# ESP32-S31 register map
Vendor: ESPRESSIF SYSTEMS (SHANGHAI) CO., LTD.; Series: ESP32 S-Series; File version: 1
CPU: RV32IMAFC r0p0, little endian, no MPU, FPU, 0 interrupt priority bits
Address unit: 32 bits
Registers are 32-bit, read-write, reset 0x0 unless marked. A register's access mark holds for its fields unless they carry their own. Offsets are from the block's base; [hi:lo] are bit positions; {n}, {i} and the like mark numbered series.

## HP_PERI1_PMS — HP_PERI1_PMS Peripheral
Base 0x2058A000
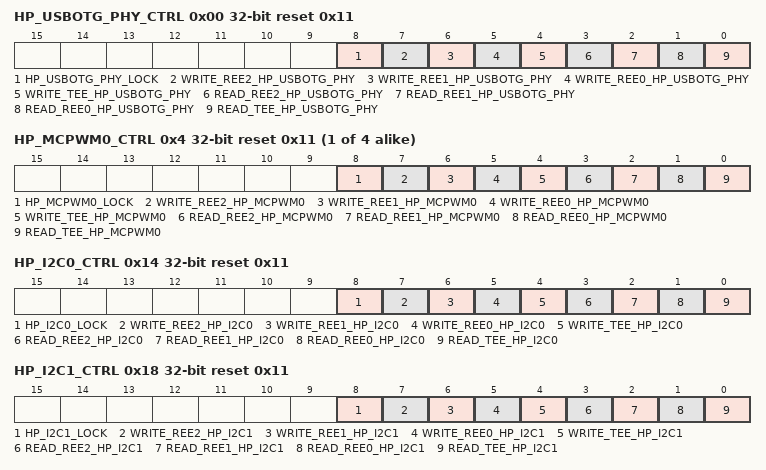
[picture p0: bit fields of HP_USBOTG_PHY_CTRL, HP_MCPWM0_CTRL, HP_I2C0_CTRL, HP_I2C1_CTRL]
0x00 HP_USBOTG_PHY_CTRL reset 0x11 — hp_usbotg_phy read/write control register
  [8] HP_USBOTG_PHY_LOCK — Set 1 to lock hp_usbotg_phy peri_apm configuration
  [7] WRITE_REE2_HP_USBOTG_PHY — Configures hp_usbotg_phy registers write permission in ree2 mode.\\ 0: can not be write \\ 1: can be write \\
  [6] WRITE_REE1_HP_USBOTG_PHY — Configures hp_usbotg_phy registers write permission in ree1 mode.\\ 0: can not be write \\ 1: can be write \\
  [5] WRITE_REE0_HP_USBOTG_PHY — Configures hp_usbotg_phy registers write permission in ree0 mode.\\ 0: can not be write \\ 1: can be write \\
  [4] WRITE_TEE_HP_USBOTG_PHY — Configures hp_usbotg_phy registers write permission in tee mode.\\ 0: can not be write \\ 1: can be write \\
  [3] READ_REE2_HP_USBOTG_PHY — Configures hp_usbotg_phy registers read permission in ree2 mode.\\ 0: can not be read \\ 1: can be read \\
  [2] READ_REE1_HP_USBOTG_PHY — Configures hp_usbotg_phy registers read permission in ree1 mode.\\ 0: can not be read \\ 1: can be read \\
  [1] READ_REE0_HP_USBOTG_PHY — Configures hp_usbotg_phy registers read permission in ree0 mode.\\ 0: can not be read \\ 1: can be read \\
  [0] READ_TEE_HP_USBOTG_PHY — Configures hp_usbotg_phy registers read permission in tee mode.\\ 0: can not be read \\ 1: can be read \\
{0x4+4i} HP_MCPWM{i}_CTRL reset 0x11 (i=0..3) — hp_mcpwm{i} read/write control register
  [8] HP_MCPWM{i}_LOCK — Set 1 to lock hp_mcpwm{i} peri_apm configuration
  [7] WRITE_REE2_HP_MCPWM{i} — Configures hp_mcpwm{i} registers write permission in ree2 mode.\\ 0: can not be write \\ 1: can be write \\
  [6] WRITE_REE1_HP_MCPWM{i} — Configures hp_mcpwm{i} registers write permission in ree1 mode.\\ 0: can not be write \\ 1: can be write \\
  [5] WRITE_REE0_HP_MCPWM{i} — Configures hp_mcpwm{i} registers write permission in ree0 mode.\\ 0: can not be write \\ 1: can be write \\
  [4] WRITE_TEE_HP_MCPWM{i} — Configures hp_mcpwm{i} registers write permission in tee mode.\\ 0: can not be write \\ 1: can be write \\
  [3] READ_REE2_HP_MCPWM{i} — Configures hp_mcpwm{i} registers read permission in ree2 mode.\\ 0: can not be read \\ 1: can be read \\
  [2] READ_REE1_HP_MCPWM{i} — Configures hp_mcpwm{i} registers read permission in ree1 mode.\\ 0: can not be read \\ 1: can be read \\
  [1] READ_REE0_HP_MCPWM{i} — Configures hp_mcpwm{i} registers read permission in ree0 mode.\\ 0: can not be read \\ 1: can be read \\
  [0] READ_TEE_HP_MCPWM{i} — Configures hp_mcpwm{i} registers read permission in tee mode.\\ 0: can not be read \\ 1: can be read \\
0x14 HP_I2C0_CTRL reset 0x11 — hp_i2c0 read/write control register
  [8] HP_I2C0_LOCK — Set 1 to lock hp_i2c0 peri_apm configuration
  [7] WRITE_REE2_HP_I2C0 — Configures hp_i2c0 registers write permission in ree2 mode.\\ 0: can not be write \\ 1: can be write \\
  [6] WRITE_REE1_HP_I2C0 — Configures hp_i2c0 registers write permission in ree1 mode.\\ 0: can not be write \\ 1: can be write \\
  [5] WRITE_REE0_HP_I2C0 — Configures hp_i2c0 registers write permission in ree0 mode.\\ 0: can not be write \\ 1: can be write \\
  [4] WRITE_TEE_HP_I2C0 — Configures hp_i2c0 registers write permission in tee mode.\\ 0: can not be write \\ 1: can be write \\
  [3] READ_REE2_HP_I2C0 — Configures hp_i2c0 registers read permission in ree2 mode.\\ 0: can not be read \\ 1: can be read \\
  [2] READ_REE1_HP_I2C0 — Configures hp_i2c0 registers read permission in ree1 mode.\\ 0: can not be read \\ 1: can be read \\
  [1] READ_REE0_HP_I2C0 — Configures hp_i2c0 registers read permission in ree0 mode.\\ 0: can not be read \\ 1: can be read \\
  [0] READ_TEE_HP_I2C0 — Configures hp_i2c0 registers read permission in tee mode.\\ 0: can not be read \\ 1: can be read \\
0x18 HP_I2C1_CTRL reset 0x11 — hp_i2c1 read/write control register
  [8] HP_I2C1_LOCK — Set 1 to lock hp_i2c1 peri_apm configuration
  [7] WRITE_REE2_HP_I2C1 — Configures hp_i2c1 registers write permission in ree2 mode.\\ 0: can not be write \\ 1: can be write \\
  [6] WRITE_REE1_HP_I2C1 — Configures hp_i2c1 registers write permission in ree1 mode.\\ 0: can not be write \\ 1: can be write \\
  [5] WRITE_REE0_HP_I2C1 — Configures hp_i2c1 registers write permission in ree0 mode.\\ 0: can not be write \\ 1: can be write \\
  [4] WRITE_TEE_HP_I2C1 — Configures hp_i2c1 registers write permission in tee mode.\\ 0: can not be write \\ 1: can be write \\
  [3] READ_REE2_HP_I2C1 — Configures hp_i2c1 registers read permission in ree2 mode.\\ 0: can not be read \\ 1: can be read \\
  [2] READ_REE1_HP_I2C1 — Configures hp_i2c1 registers read permission in ree1 mode.\\ 0: can not be read \\ 1: can be read \\
  [1] READ_REE0_HP_I2C1 — Configures hp_i2c1 registers read permission in ree0 mode.\\ 0: can not be read \\ 1: can be read \\
  [0] READ_TEE_HP_I2C1 — Configures hp_i2c1 registers read permission in tee mode.\\ 0: can not be read \\ 1: can be read \\
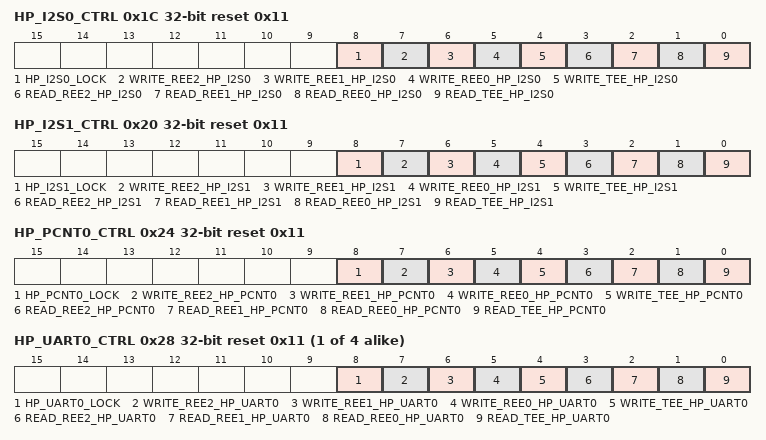
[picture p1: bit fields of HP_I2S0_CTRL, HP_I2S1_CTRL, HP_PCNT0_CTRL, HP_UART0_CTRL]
0x1C HP_I2S0_CTRL reset 0x11 — hp_i2s0 read/write control register
  [8] HP_I2S0_LOCK — Set 1 to lock hp_i2s0 peri_apm configuration
  [7] WRITE_REE2_HP_I2S0 — Configures hp_i2s0 registers write permission in ree2 mode.\\ 0: can not be write \\ 1: can be write \\
  [6] WRITE_REE1_HP_I2S0 — Configures hp_i2s0 registers write permission in ree1 mode.\\ 0: can not be write \\ 1: can be write \\
  [5] WRITE_REE0_HP_I2S0 — Configures hp_i2s0 registers write permission in ree0 mode.\\ 0: can not be write \\ 1: can be write \\
  [4] WRITE_TEE_HP_I2S0 — Configures hp_i2s0 registers write permission in tee mode.\\ 0: can not be write \\ 1: can be write \\
  [3] READ_REE2_HP_I2S0 — Configures hp_i2s0 registers read permission in ree2 mode.\\ 0: can not be read \\ 1: can be read \\
  [2] READ_REE1_HP_I2S0 — Configures hp_i2s0 registers read permission in ree1 mode.\\ 0: can not be read \\ 1: can be read \\
  [1] READ_REE0_HP_I2S0 — Configures hp_i2s0 registers read permission in ree0 mode.\\ 0: can not be read \\ 1: can be read \\
  [0] READ_TEE_HP_I2S0 — Configures hp_i2s0 registers read permission in tee mode.\\ 0: can not be read \\ 1: can be read \\
0x20 HP_I2S1_CTRL reset 0x11 — hp_i2s1 read/write control register
  [8] HP_I2S1_LOCK — Set 1 to lock hp_i2s1 peri_apm configuration
  [7] WRITE_REE2_HP_I2S1 — Configures hp_i2s1 registers write permission in ree2 mode.\\ 0: can not be write \\ 1: can be write \\
  [6] WRITE_REE1_HP_I2S1 — Configures hp_i2s1 registers write permission in ree1 mode.\\ 0: can not be write \\ 1: can be write \\
  [5] WRITE_REE0_HP_I2S1 — Configures hp_i2s1 registers write permission in ree0 mode.\\ 0: can not be write \\ 1: can be write \\
  [4] WRITE_TEE_HP_I2S1 — Configures hp_i2s1 registers write permission in tee mode.\\ 0: can not be write \\ 1: can be write \\
  [3] READ_REE2_HP_I2S1 — Configures hp_i2s1 registers read permission in ree2 mode.\\ 0: can not be read \\ 1: can be read \\
  [2] READ_REE1_HP_I2S1 — Configures hp_i2s1 registers read permission in ree1 mode.\\ 0: can not be read \\ 1: can be read \\
  [1] READ_REE0_HP_I2S1 — Configures hp_i2s1 registers read permission in ree0 mode.\\ 0: can not be read \\ 1: can be read \\
  [0] READ_TEE_HP_I2S1 — Configures hp_i2s1 registers read permission in tee mode.\\ 0: can not be read \\ 1: can be read \\
0x24 HP_PCNT0_CTRL reset 0x11 — hp_pcnt0 read/write control register
  [8] HP_PCNT0_LOCK — Set 1 to lock hp_pcnt0 peri_apm configuration
  [7] WRITE_REE2_HP_PCNT0 — Configures hp_pcnt0 registers write permission in ree2 mode.\\ 0: can not be write \\ 1: can be write \\
  [6] WRITE_REE1_HP_PCNT0 — Configures hp_pcnt0 registers write permission in ree1 mode.\\ 0: can not be write \\ 1: can be write \\
  [5] WRITE_REE0_HP_PCNT0 — Configures hp_pcnt0 registers write permission in ree0 mode.\\ 0: can not be write \\ 1: can be write \\
  [4] WRITE_TEE_HP_PCNT0 — Configures hp_pcnt0 registers write permission in tee mode.\\ 0: can not be write \\ 1: can be write \\
  [3] READ_REE2_HP_PCNT0 — Configures hp_pcnt0 registers read permission in ree2 mode.\\ 0: can not be read \\ 1: can be read \\
  [2] READ_REE1_HP_PCNT0 — Configures hp_pcnt0 registers read permission in ree1 mode.\\ 0: can not be read \\ 1: can be read \\
  [1] READ_REE0_HP_PCNT0 — Configures hp_pcnt0 registers read permission in ree0 mode.\\ 0: can not be read \\ 1: can be read \\
  [0] READ_TEE_HP_PCNT0 — Configures hp_pcnt0 registers read permission in tee mode.\\ 0: can not be read \\ 1: can be read \\
{0x28+4i} HP_UART{i}_CTRL reset 0x11 (i=0..3) — hp_uart{i} read/write control register
  [8] HP_UART{i}_LOCK — Set 1 to lock hp_uart{i} peri_apm configuration
  [7] WRITE_REE2_HP_UART{i} — Configures hp_uart{i} registers write permission in ree2 mode.\\ 0: can not be write \\ 1: can be write \\
  [6] WRITE_REE1_HP_UART{i} — Configures hp_uart{i} registers write permission in ree1 mode.\\ 0: can not be write \\ 1: can be write \\
  [5] WRITE_REE0_HP_UART{i} — Configures hp_uart{i} registers write permission in ree0 mode.\\ 0: can not be write \\ 1: can be write \\
  [4] WRITE_TEE_HP_UART{i} — Configures hp_uart{i} registers write permission in tee mode.\\ 0: can not be write \\ 1: can be write \\
  [3] READ_REE2_HP_UART{i} — Configures hp_uart{i} registers read permission in ree2 mode.\\ 0: can not be read \\ 1: can be read \\
  [2] READ_REE1_HP_UART{i} — Configures hp_uart{i} registers read permission in ree1 mode.\\ 0: can not be read \\ 1: can be read \\
  [1] READ_REE0_HP_UART{i} — Configures hp_uart{i} registers read permission in ree0 mode.\\ 0: can not be read \\ 1: can be read \\
  [0] READ_TEE_HP_UART{i} — Configures hp_uart{i} registers read permission in tee mode.\\ 0: can not be read \\ 1: can be read \\
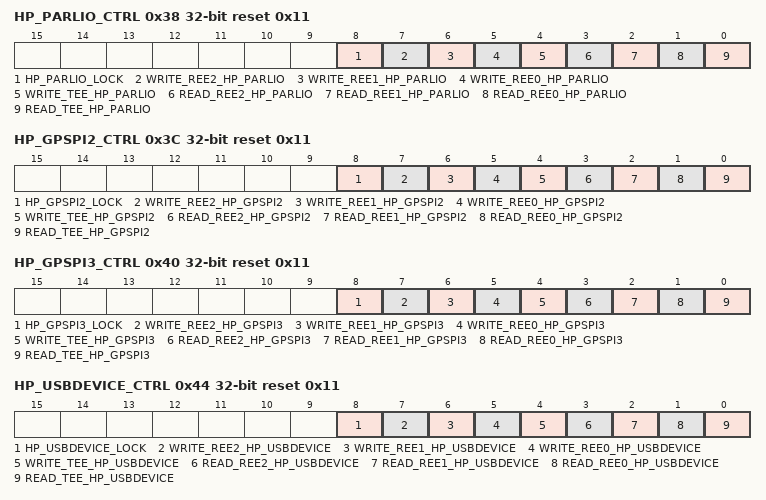
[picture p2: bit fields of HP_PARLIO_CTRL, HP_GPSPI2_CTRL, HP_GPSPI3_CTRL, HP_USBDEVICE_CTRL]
0x38 HP_PARLIO_CTRL reset 0x11 — hp_parlio read/write control register
  [8] HP_PARLIO_LOCK — Set 1 to lock hp_parlio peri_apm configuration
  [7] WRITE_REE2_HP_PARLIO — Configures hp_parlio registers write permission in ree2 mode.\\ 0: can not be write \\ 1: can be write \\
  [6] WRITE_REE1_HP_PARLIO — Configures hp_parlio registers write permission in ree1 mode.\\ 0: can not be write \\ 1: can be write \\
  [5] WRITE_REE0_HP_PARLIO — Configures hp_parlio registers write permission in ree0 mode.\\ 0: can not be write \\ 1: can be write \\
  [4] WRITE_TEE_HP_PARLIO — Configures hp_parlio registers write permission in tee mode.\\ 0: can not be write \\ 1: can be write \\
  [3] READ_REE2_HP_PARLIO — Configures hp_parlio registers read permission in ree2 mode.\\ 0: can not be read \\ 1: can be read \\
  [2] READ_REE1_HP_PARLIO — Configures hp_parlio registers read permission in ree1 mode.\\ 0: can not be read \\ 1: can be read \\
  [1] READ_REE0_HP_PARLIO — Configures hp_parlio registers read permission in ree0 mode.\\ 0: can not be read \\ 1: can be read \\
  [0] READ_TEE_HP_PARLIO — Configures hp_parlio registers read permission in tee mode.\\ 0: can not be read \\ 1: can be read \\
0x3C HP_GPSPI2_CTRL reset 0x11 — hp_gpspi2 read/write control register
  [8] HP_GPSPI2_LOCK — Set 1 to lock hp_gpspi2 peri_apm configuration
  [7] WRITE_REE2_HP_GPSPI2 — Configures hp_gpspi2 registers write permission in ree2 mode.\\ 0: can not be write \\ 1: can be write \\
  [6] WRITE_REE1_HP_GPSPI2 — Configures hp_gpspi2 registers write permission in ree1 mode.\\ 0: can not be write \\ 1: can be write \\
  [5] WRITE_REE0_HP_GPSPI2 — Configures hp_gpspi2 registers write permission in ree0 mode.\\ 0: can not be write \\ 1: can be write \\
  [4] WRITE_TEE_HP_GPSPI2 — Configures hp_gpspi2 registers write permission in tee mode.\\ 0: can not be write \\ 1: can be write \\
  [3] READ_REE2_HP_GPSPI2 — Configures hp_gpspi2 registers read permission in ree2 mode.\\ 0: can not be read \\ 1: can be read \\
  [2] READ_REE1_HP_GPSPI2 — Configures hp_gpspi2 registers read permission in ree1 mode.\\ 0: can not be read \\ 1: can be read \\
  [1] READ_REE0_HP_GPSPI2 — Configures hp_gpspi2 registers read permission in ree0 mode.\\ 0: can not be read \\ 1: can be read \\
  [0] READ_TEE_HP_GPSPI2 — Configures hp_gpspi2 registers read permission in tee mode.\\ 0: can not be read \\ 1: can be read \\
0x40 HP_GPSPI3_CTRL reset 0x11 — hp_gpspi3 read/write control register
  [8] HP_GPSPI3_LOCK — Set 1 to lock hp_gpspi3 peri_apm configuration
  [7] WRITE_REE2_HP_GPSPI3 — Configures hp_gpspi3 registers write permission in ree2 mode.\\ 0: can not be write \\ 1: can be write \\
  [6] WRITE_REE1_HP_GPSPI3 — Configures hp_gpspi3 registers write permission in ree1 mode.\\ 0: can not be write \\ 1: can be write \\
  [5] WRITE_REE0_HP_GPSPI3 — Configures hp_gpspi3 registers write permission in ree0 mode.\\ 0: can not be write \\ 1: can be write \\
  [4] WRITE_TEE_HP_GPSPI3 — Configures hp_gpspi3 registers write permission in tee mode.\\ 0: can not be write \\ 1: can be write \\
  [3] READ_REE2_HP_GPSPI3 — Configures hp_gpspi3 registers read permission in ree2 mode.\\ 0: can not be read \\ 1: can be read \\
  [2] READ_REE1_HP_GPSPI3 — Configures hp_gpspi3 registers read permission in ree1 mode.\\ 0: can not be read \\ 1: can be read \\
  [1] READ_REE0_HP_GPSPI3 — Configures hp_gpspi3 registers read permission in ree0 mode.\\ 0: can not be read \\ 1: can be read \\
  [0] READ_TEE_HP_GPSPI3 — Configures hp_gpspi3 registers read permission in tee mode.\\ 0: can not be read \\ 1: can be read \\
0x44 HP_USBDEVICE_CTRL reset 0x11 — hp_usbdevice read/write control register
  [8] HP_USBDEVICE_LOCK — Set 1 to lock hp_usbdevice peri_apm configuration
  [7] WRITE_REE2_HP_USBDEVICE — Configures hp_usbdevice registers write permission in ree2 mode.\\ 0: can not be write \\ 1: can be write \\
  [6] WRITE_REE1_HP_USBDEVICE — Configures hp_usbdevice registers write permission in ree1 mode.\\ 0: can not be write \\ 1: can be write \\
  [5] WRITE_REE0_HP_USBDEVICE — Configures hp_usbdevice registers write permission in ree0 mode.\\ 0: can not be write \\ 1: can be write \\
  [4] WRITE_TEE_HP_USBDEVICE — Configures hp_usbdevice registers write permission in tee mode.\\ 0: can not be write \\ 1: can be write \\
  [3] READ_REE2_HP_USBDEVICE — Configures hp_usbdevice registers read permission in ree2 mode.\\ 0: can not be read \\ 1: can be read \\
  [2] READ_REE1_HP_USBDEVICE — Configures hp_usbdevice registers read permission in ree1 mode.\\ 0: can not be read \\ 1: can be read \\
  [1] READ_REE0_HP_USBDEVICE — Configures hp_usbdevice registers read permission in ree0 mode.\\ 0: can not be read \\ 1: can be read \\
  [0] READ_TEE_HP_USBDEVICE — Configures hp_usbdevice registers read permission in tee mode.\\ 0: can not be read \\ 1: can be read \\
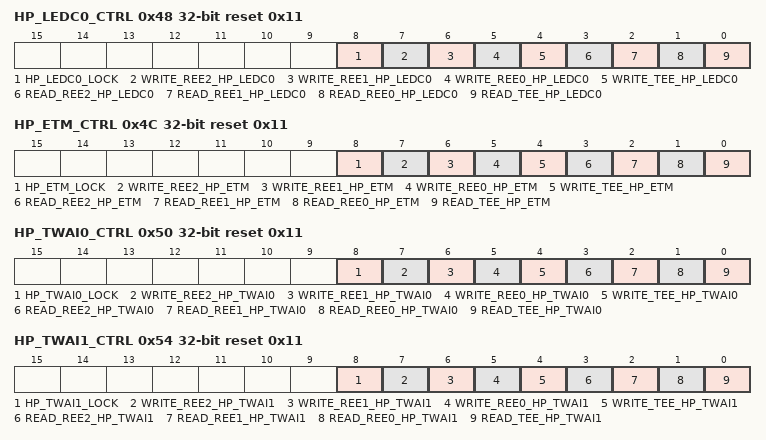
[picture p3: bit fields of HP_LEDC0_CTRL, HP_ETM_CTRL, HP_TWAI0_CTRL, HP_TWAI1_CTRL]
0x48 HP_LEDC0_CTRL reset 0x11 — hp_ledc0 read/write control register
  [8] HP_LEDC0_LOCK — Set 1 to lock hp_ledc0 peri_apm configuration
  [7] WRITE_REE2_HP_LEDC0 — Configures hp_ledc0 registers write permission in ree2 mode.\\ 0: can not be write \\ 1: can be write \\
  [6] WRITE_REE1_HP_LEDC0 — Configures hp_ledc0 registers write permission in ree1 mode.\\ 0: can not be write \\ 1: can be write \\
  [5] WRITE_REE0_HP_LEDC0 — Configures hp_ledc0 registers write permission in ree0 mode.\\ 0: can not be write \\ 1: can be write \\
  [4] WRITE_TEE_HP_LEDC0 — Configures hp_ledc0 registers write permission in tee mode.\\ 0: can not be write \\ 1: can be write \\
  [3] READ_REE2_HP_LEDC0 — Configures hp_ledc0 registers read permission in ree2 mode.\\ 0: can not be read \\ 1: can be read \\
  [2] READ_REE1_HP_LEDC0 — Configures hp_ledc0 registers read permission in ree1 mode.\\ 0: can not be read \\ 1: can be read \\
  [1] READ_REE0_HP_LEDC0 — Configures hp_ledc0 registers read permission in ree0 mode.\\ 0: can not be read \\ 1: can be read \\
  [0] READ_TEE_HP_LEDC0 — Configures hp_ledc0 registers read permission in tee mode.\\ 0: can not be read \\ 1: can be read \\
0x4C HP_ETM_CTRL reset 0x11 — hp_etm read/write control register
  [8] HP_ETM_LOCK — Set 1 to lock hp_etm peri_apm configuration
  [7] WRITE_REE2_HP_ETM — Configures hp_etm registers write permission in ree2 mode.\\ 0: can not be write \\ 1: can be write \\
  [6] WRITE_REE1_HP_ETM — Configures hp_etm registers write permission in ree1 mode.\\ 0: can not be write \\ 1: can be write \\
  [5] WRITE_REE0_HP_ETM — Configures hp_etm registers write permission in ree0 mode.\\ 0: can not be write \\ 1: can be write \\
  [4] WRITE_TEE_HP_ETM — Configures hp_etm registers write permission in tee mode.\\ 0: can not be write \\ 1: can be write \\
  [3] READ_REE2_HP_ETM — Configures hp_etm registers read permission in ree2 mode.\\ 0: can not be read \\ 1: can be read \\
  [2] READ_REE1_HP_ETM — Configures hp_etm registers read permission in ree1 mode.\\ 0: can not be read \\ 1: can be read \\
  [1] READ_REE0_HP_ETM — Configures hp_etm registers read permission in ree0 mode.\\ 0: can not be read \\ 1: can be read \\
  [0] READ_TEE_HP_ETM — Configures hp_etm registers read permission in tee mode.\\ 0: can not be read \\ 1: can be read \\
0x50 HP_TWAI0_CTRL reset 0x11 — hp_twai0 read/write control register
  [8] HP_TWAI0_LOCK — Set 1 to lock hp_twai0 peri_apm configuration
  [7] WRITE_REE2_HP_TWAI0 — Configures hp_twai0 registers write permission in ree2 mode.\\ 0: can not be write \\ 1: can be write \\
  [6] WRITE_REE1_HP_TWAI0 — Configures hp_twai0 registers write permission in ree1 mode.\\ 0: can not be write \\ 1: can be write \\
  [5] WRITE_REE0_HP_TWAI0 — Configures hp_twai0 registers write permission in ree0 mode.\\ 0: can not be write \\ 1: can be write \\
  [4] WRITE_TEE_HP_TWAI0 — Configures hp_twai0 registers write permission in tee mode.\\ 0: can not be write \\ 1: can be write \\
  [3] READ_REE2_HP_TWAI0 — Configures hp_twai0 registers read permission in ree2 mode.\\ 0: can not be read \\ 1: can be read \\
  [2] READ_REE1_HP_TWAI0 — Configures hp_twai0 registers read permission in ree1 mode.\\ 0: can not be read \\ 1: can be read \\
  [1] READ_REE0_HP_TWAI0 — Configures hp_twai0 registers read permission in ree0 mode.\\ 0: can not be read \\ 1: can be read \\
  [0] READ_TEE_HP_TWAI0 — Configures hp_twai0 registers read permission in tee mode.\\ 0: can not be read \\ 1: can be read \\
0x54 HP_TWAI1_CTRL reset 0x11 — hp_twai1 read/write control register
  [8] HP_TWAI1_LOCK — Set 1 to lock hp_twai1 peri_apm configuration
  [7] WRITE_REE2_HP_TWAI1 — Configures hp_twai1 registers write permission in ree2 mode.\\ 0: can not be write \\ 1: can be write \\
  [6] WRITE_REE1_HP_TWAI1 — Configures hp_twai1 registers write permission in ree1 mode.\\ 0: can not be write \\ 1: can be write \\
  [5] WRITE_REE0_HP_TWAI1 — Configures hp_twai1 registers write permission in ree0 mode.\\ 0: can not be write \\ 1: can be write \\
  [4] WRITE_TEE_HP_TWAI1 — Configures hp_twai1 registers write permission in tee mode.\\ 0: can not be write \\ 1: can be write \\
  [3] READ_REE2_HP_TWAI1 — Configures hp_twai1 registers read permission in ree2 mode.\\ 0: can not be read \\ 1: can be read \\
  [2] READ_REE1_HP_TWAI1 — Configures hp_twai1 registers read permission in ree1 mode.\\ 0: can not be read \\ 1: can be read \\
  [1] READ_REE0_HP_TWAI1 — Configures hp_twai1 registers read permission in ree0 mode.\\ 0: can not be read \\ 1: can be read \\
  [0] READ_TEE_HP_TWAI1 — Configures hp_twai1 registers read permission in tee mode.\\ 0: can not be read \\ 1: can be read \\
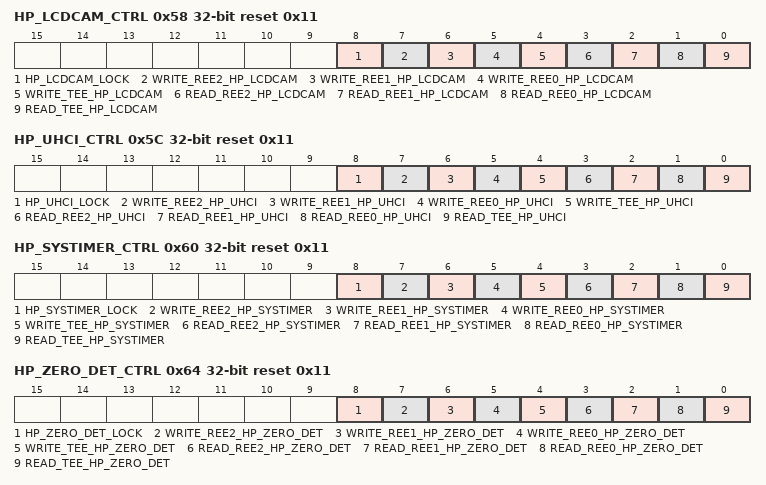
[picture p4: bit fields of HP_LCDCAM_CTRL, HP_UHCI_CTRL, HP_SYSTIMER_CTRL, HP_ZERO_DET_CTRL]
0x58 HP_LCDCAM_CTRL reset 0x11 — hp_lcdcam read/write control register
  [8] HP_LCDCAM_LOCK — Set 1 to lock hp_lcdcam peri_apm configuration
  [7] WRITE_REE2_HP_LCDCAM — Configures hp_lcdcam registers write permission in ree2 mode.\\ 0: can not be write \\ 1: can be write \\
  [6] WRITE_REE1_HP_LCDCAM — Configures hp_lcdcam registers write permission in ree1 mode.\\ 0: can not be write \\ 1: can be write \\
  [5] WRITE_REE0_HP_LCDCAM — Configures hp_lcdcam registers write permission in ree0 mode.\\ 0: can not be write \\ 1: can be write \\
  [4] WRITE_TEE_HP_LCDCAM — Configures hp_lcdcam registers write permission in tee mode.\\ 0: can not be write \\ 1: can be write \\
  [3] READ_REE2_HP_LCDCAM — Configures hp_lcdcam registers read permission in ree2 mode.\\ 0: can not be read \\ 1: can be read \\
  [2] READ_REE1_HP_LCDCAM — Configures hp_lcdcam registers read permission in ree1 mode.\\ 0: can not be read \\ 1: can be read \\
  [1] READ_REE0_HP_LCDCAM — Configures hp_lcdcam registers read permission in ree0 mode.\\ 0: can not be read \\ 1: can be read \\
  [0] READ_TEE_HP_LCDCAM — Configures hp_lcdcam registers read permission in tee mode.\\ 0: can not be read \\ 1: can be read \\
0x5C HP_UHCI_CTRL reset 0x11 — hp_uhci read/write control register
  [8] HP_UHCI_LOCK — Set 1 to lock hp_uhci peri_apm configuration
  [7] WRITE_REE2_HP_UHCI — Configures hp_uhci registers write permission in ree2 mode.\\ 0: can not be write \\ 1: can be write \\
  [6] WRITE_REE1_HP_UHCI — Configures hp_uhci registers write permission in ree1 mode.\\ 0: can not be write \\ 1: can be write \\
  [5] WRITE_REE0_HP_UHCI — Configures hp_uhci registers write permission in ree0 mode.\\ 0: can not be write \\ 1: can be write \\
  [4] WRITE_TEE_HP_UHCI — Configures hp_uhci registers write permission in tee mode.\\ 0: can not be write \\ 1: can be write \\
  [3] READ_REE2_HP_UHCI — Configures hp_uhci registers read permission in ree2 mode.\\ 0: can not be read \\ 1: can be read \\
  [2] READ_REE1_HP_UHCI — Configures hp_uhci registers read permission in ree1 mode.\\ 0: can not be read \\ 1: can be read \\
  [1] READ_REE0_HP_UHCI — Configures hp_uhci registers read permission in ree0 mode.\\ 0: can not be read \\ 1: can be read \\
  [0] READ_TEE_HP_UHCI — Configures hp_uhci registers read permission in tee mode.\\ 0: can not be read \\ 1: can be read \\
0x60 HP_SYSTIMER_CTRL reset 0x11 — hp_systimer read/write control register
  [8] HP_SYSTIMER_LOCK — Set 1 to lock hp_systimer peri_apm configuration
  [7] WRITE_REE2_HP_SYSTIMER — Configures hp_systimer registers write permission in ree2 mode.\\ 0: can not be write \\ 1: can be write \\
  [6] WRITE_REE1_HP_SYSTIMER — Configures hp_systimer registers write permission in ree1 mode.\\ 0: can not be write \\ 1: can be write \\
  [5] WRITE_REE0_HP_SYSTIMER — Configures hp_systimer registers write permission in ree0 mode.\\ 0: can not be write \\ 1: can be write \\
  [4] WRITE_TEE_HP_SYSTIMER — Configures hp_systimer registers write permission in tee mode.\\ 0: can not be write \\ 1: can be write \\
  [3] READ_REE2_HP_SYSTIMER — Configures hp_systimer registers read permission in ree2 mode.\\ 0: can not be read \\ 1: can be read \\
  [2] READ_REE1_HP_SYSTIMER — Configures hp_systimer registers read permission in ree1 mode.\\ 0: can not be read \\ 1: can be read \\
  [1] READ_REE0_HP_SYSTIMER — Configures hp_systimer registers read permission in ree0 mode.\\ 0: can not be read \\ 1: can be read \\
  [0] READ_TEE_HP_SYSTIMER — Configures hp_systimer registers read permission in tee mode.\\ 0: can not be read \\ 1: can be read \\
0x64 HP_ZERO_DET_CTRL reset 0x11 — hp_zero_det read/write control register
  [8] HP_ZERO_DET_LOCK — Set 1 to lock hp_zero_det peri_apm configuration
  [7] WRITE_REE2_HP_ZERO_DET — Configures hp_zero_det registers write permission in ree2 mode.\\ 0: can not be write \\ 1: can be write \\
  [6] WRITE_REE1_HP_ZERO_DET — Configures hp_zero_det registers write permission in ree1 mode.\\ 0: can not be write \\ 1: can be write \\
  [5] WRITE_REE0_HP_ZERO_DET — Configures hp_zero_det registers write permission in ree0 mode.\\ 0: can not be write \\ 1: can be write \\
  [4] WRITE_TEE_HP_ZERO_DET — Configures hp_zero_det registers write permission in tee mode.\\ 0: can not be write \\ 1: can be write \\
  [3] READ_REE2_HP_ZERO_DET — Configures hp_zero_det registers read permission in ree2 mode.\\ 0: can not be read \\ 1: can be read \\
  [2] READ_REE1_HP_ZERO_DET — Configures hp_zero_det registers read permission in ree1 mode.\\ 0: can not be read \\ 1: can be read \\
  [1] READ_REE0_HP_ZERO_DET — Configures hp_zero_det registers read permission in ree0 mode.\\ 0: can not be read \\ 1: can be read \\
  [0] READ_TEE_HP_ZERO_DET — Configures hp_zero_det registers read permission in tee mode.\\ 0: can not be read \\ 1: can be read \\
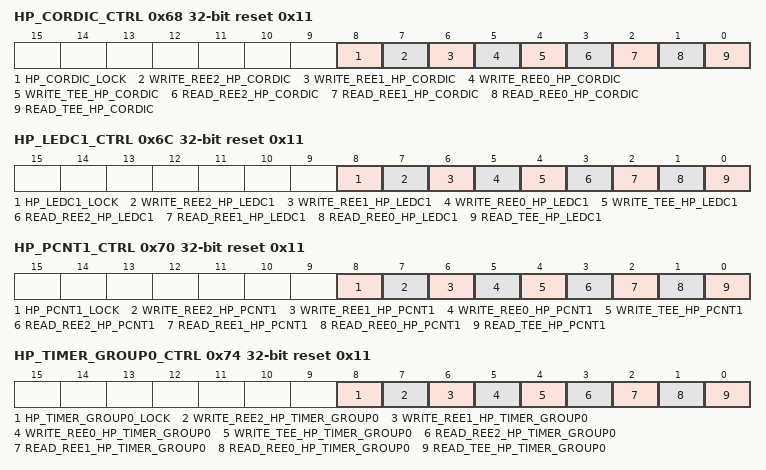
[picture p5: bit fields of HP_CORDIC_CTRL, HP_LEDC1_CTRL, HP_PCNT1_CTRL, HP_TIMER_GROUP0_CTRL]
0x68 HP_CORDIC_CTRL reset 0x11 — hp_cordic read/write control register
  [8] HP_CORDIC_LOCK — Set 1 to lock hp_cordic peri_apm configuration
  [7] WRITE_REE2_HP_CORDIC — Configures hp_cordic registers write permission in ree2 mode.\\ 0: can not be write \\ 1: can be write \\
  [6] WRITE_REE1_HP_CORDIC — Configures hp_cordic registers write permission in ree1 mode.\\ 0: can not be write \\ 1: can be write \\
  [5] WRITE_REE0_HP_CORDIC — Configures hp_cordic registers write permission in ree0 mode.\\ 0: can not be write \\ 1: can be write \\
  [4] WRITE_TEE_HP_CORDIC — Configures hp_cordic registers write permission in tee mode.\\ 0: can not be write \\ 1: can be write \\
  [3] READ_REE2_HP_CORDIC — Configures hp_cordic registers read permission in ree2 mode.\\ 0: can not be read \\ 1: can be read \\
  [2] READ_REE1_HP_CORDIC — Configures hp_cordic registers read permission in ree1 mode.\\ 0: can not be read \\ 1: can be read \\
  [1] READ_REE0_HP_CORDIC — Configures hp_cordic registers read permission in ree0 mode.\\ 0: can not be read \\ 1: can be read \\
  [0] READ_TEE_HP_CORDIC — Configures hp_cordic registers read permission in tee mode.\\ 0: can not be read \\ 1: can be read \\
0x6C HP_LEDC1_CTRL reset 0x11 — hp_ledc1 read/write control register
  [8] HP_LEDC1_LOCK — Set 1 to lock hp_ledc1 peri_apm configuration
  [7] WRITE_REE2_HP_LEDC1 — Configures hp_ledc1 registers write permission in ree2 mode.\\ 0: can not be write \\ 1: can be write \\
  [6] WRITE_REE1_HP_LEDC1 — Configures hp_ledc1 registers write permission in ree1 mode.\\ 0: can not be write \\ 1: can be write \\
  [5] WRITE_REE0_HP_LEDC1 — Configures hp_ledc1 registers write permission in ree0 mode.\\ 0: can not be write \\ 1: can be write \\
  [4] WRITE_TEE_HP_LEDC1 — Configures hp_ledc1 registers write permission in tee mode.\\ 0: can not be write \\ 1: can be write \\
  [3] READ_REE2_HP_LEDC1 — Configures hp_ledc1 registers read permission in ree2 mode.\\ 0: can not be read \\ 1: can be read \\
  [2] READ_REE1_HP_LEDC1 — Configures hp_ledc1 registers read permission in ree1 mode.\\ 0: can not be read \\ 1: can be read \\
  [1] READ_REE0_HP_LEDC1 — Configures hp_ledc1 registers read permission in ree0 mode.\\ 0: can not be read \\ 1: can be read \\
  [0] READ_TEE_HP_LEDC1 — Configures hp_ledc1 registers read permission in tee mode.\\ 0: can not be read \\ 1: can be read \\
0x70 HP_PCNT1_CTRL reset 0x11 — hp_pcnt1 read/write control register
  [8] HP_PCNT1_LOCK — Set 1 to lock hp_pcnt1 peri_apm configuration
  [7] WRITE_REE2_HP_PCNT1 — Configures hp_pcnt1 registers write permission in ree2 mode.\\ 0: can not be write \\ 1: can be write \\
  [6] WRITE_REE1_HP_PCNT1 — Configures hp_pcnt1 registers write permission in ree1 mode.\\ 0: can not be write \\ 1: can be write \\
  [5] WRITE_REE0_HP_PCNT1 — Configures hp_pcnt1 registers write permission in ree0 mode.\\ 0: can not be write \\ 1: can be write \\
  [4] WRITE_TEE_HP_PCNT1 — Configures hp_pcnt1 registers write permission in tee mode.\\ 0: can not be write \\ 1: can be write \\
  [3] READ_REE2_HP_PCNT1 — Configures hp_pcnt1 registers read permission in ree2 mode.\\ 0: can not be read \\ 1: can be read \\
  [2] READ_REE1_HP_PCNT1 — Configures hp_pcnt1 registers read permission in ree1 mode.\\ 0: can not be read \\ 1: can be read \\
  [1] READ_REE0_HP_PCNT1 — Configures hp_pcnt1 registers read permission in ree0 mode.\\ 0: can not be read \\ 1: can be read \\
  [0] READ_TEE_HP_PCNT1 — Configures hp_pcnt1 registers read permission in tee mode.\\ 0: can not be read \\ 1: can be read \\
0x74 HP_TIMER_GROUP0_CTRL reset 0x11 — hp_timer_group0 read/write control register
  [8] HP_TIMER_GROUP0_LOCK — Set 1 to lock hp_timer_group0 peri_apm configuration
  [7] WRITE_REE2_HP_TIMER_GROUP0 — Configures hp_timer_group0 registers write permission in ree2 mode.\\ 0: can not be write \\ 1: can be write \\
  [6] WRITE_REE1_HP_TIMER_GROUP0 — Configures hp_timer_group0 registers write permission in ree1 mode.\\ 0: can not be write \\ 1: can be write \\
  [5] WRITE_REE0_HP_TIMER_GROUP0 — Configures hp_timer_group0 registers write permission in ree0 mode.\\ 0: can not be write \\ 1: can be write \\
  [4] WRITE_TEE_HP_TIMER_GROUP0 — Configures hp_timer_group0 registers write permission in tee mode.\\ 0: can not be write \\ 1: can be write \\
  [3] READ_REE2_HP_TIMER_GROUP0 — Configures hp_timer_group0 registers read permission in ree2 mode.\\ 0: can not be read \\ 1: can be read \\
  [2] READ_REE1_HP_TIMER_GROUP0 — Configures hp_timer_group0 registers read permission in ree1 mode.\\ 0: can not be read \\ 1: can be read \\
  [1] READ_REE0_HP_TIMER_GROUP0 — Configures hp_timer_group0 registers read permission in ree0 mode.\\ 0: can not be read \\ 1: can be read \\
  [0] READ_TEE_HP_TIMER_GROUP0 — Configures hp_timer_group0 registers read permission in tee mode.\\ 0: can not be read \\ 1: can be read \\
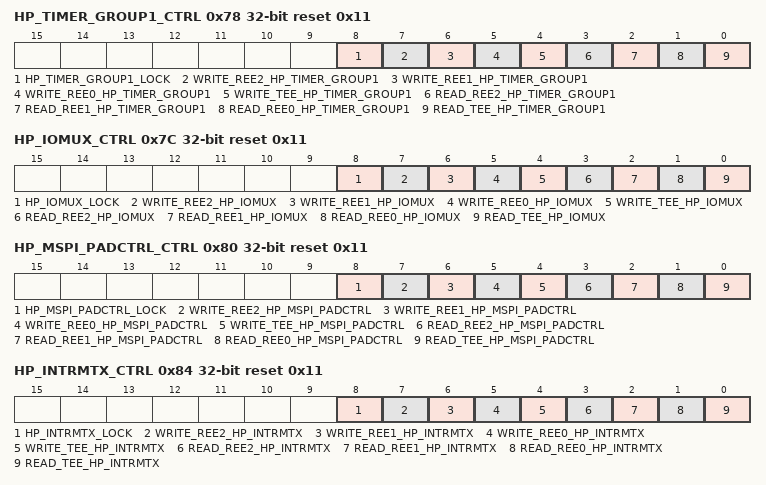
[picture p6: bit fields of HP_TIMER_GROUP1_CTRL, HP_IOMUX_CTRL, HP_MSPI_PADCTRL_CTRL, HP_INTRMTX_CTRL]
0x78 HP_TIMER_GROUP1_CTRL reset 0x11 — hp_timer_group1 read/write control register
  [8] HP_TIMER_GROUP1_LOCK — Set 1 to lock hp_timer_group1 peri_apm configuration
  [7] WRITE_REE2_HP_TIMER_GROUP1 — Configures hp_timer_group1 registers write permission in ree2 mode.\\ 0: can not be write \\ 1: can be write \\
  [6] WRITE_REE1_HP_TIMER_GROUP1 — Configures hp_timer_group1 registers write permission in ree1 mode.\\ 0: can not be write \\ 1: can be write \\
  [5] WRITE_REE0_HP_TIMER_GROUP1 — Configures hp_timer_group1 registers write permission in ree0 mode.\\ 0: can not be write \\ 1: can be write \\
  [4] WRITE_TEE_HP_TIMER_GROUP1 — Configures hp_timer_group1 registers write permission in tee mode.\\ 0: can not be write \\ 1: can be write \\
  [3] READ_REE2_HP_TIMER_GROUP1 — Configures hp_timer_group1 registers read permission in ree2 mode.\\ 0: can not be read \\ 1: can be read \\
  [2] READ_REE1_HP_TIMER_GROUP1 — Configures hp_timer_group1 registers read permission in ree1 mode.\\ 0: can not be read \\ 1: can be read \\
  [1] READ_REE0_HP_TIMER_GROUP1 — Configures hp_timer_group1 registers read permission in ree0 mode.\\ 0: can not be read \\ 1: can be read \\
  [0] READ_TEE_HP_TIMER_GROUP1 — Configures hp_timer_group1 registers read permission in tee mode.\\ 0: can not be read \\ 1: can be read \\
0x7C HP_IOMUX_CTRL reset 0x11 — hp_iomux read/write control register
  [8] HP_IOMUX_LOCK — Set 1 to lock hp_iomux peri_apm configuration
  [7] WRITE_REE2_HP_IOMUX — Configures hp_iomux registers write permission in ree2 mode.\\ 0: can not be write \\ 1: can be write \\
  [6] WRITE_REE1_HP_IOMUX — Configures hp_iomux registers write permission in ree1 mode.\\ 0: can not be write \\ 1: can be write \\
  [5] WRITE_REE0_HP_IOMUX — Configures hp_iomux registers write permission in ree0 mode.\\ 0: can not be write \\ 1: can be write \\
  [4] WRITE_TEE_HP_IOMUX — Configures hp_iomux registers write permission in tee mode.\\ 0: can not be write \\ 1: can be write \\
  [3] READ_REE2_HP_IOMUX — Configures hp_iomux registers read permission in ree2 mode.\\ 0: can not be read \\ 1: can be read \\
  [2] READ_REE1_HP_IOMUX — Configures hp_iomux registers read permission in ree1 mode.\\ 0: can not be read \\ 1: can be read \\
  [1] READ_REE0_HP_IOMUX — Configures hp_iomux registers read permission in ree0 mode.\\ 0: can not be read \\ 1: can be read \\
  [0] READ_TEE_HP_IOMUX — Configures hp_iomux registers read permission in tee mode.\\ 0: can not be read \\ 1: can be read \\
0x80 HP_MSPI_PADCTRL_CTRL reset 0x11 — hp_mspi_padctrl read/write control register
  [8] HP_MSPI_PADCTRL_LOCK — Set 1 to lock hp_mspi_padctrl peri_apm configuration
  [7] WRITE_REE2_HP_MSPI_PADCTRL — Configures hp_mspi_padctrl registers write permission in ree2 mode.\\ 0: can not be write \\ 1: can be write \\
  [6] WRITE_REE1_HP_MSPI_PADCTRL — Configures hp_mspi_padctrl registers write permission in ree1 mode.\\ 0: can not be write \\ 1: can be write \\
  [5] WRITE_REE0_HP_MSPI_PADCTRL — Configures hp_mspi_padctrl registers write permission in ree0 mode.\\ 0: can not be write \\ 1: can be write \\
  [4] WRITE_TEE_HP_MSPI_PADCTRL — Configures hp_mspi_padctrl registers write permission in tee mode.\\ 0: can not be write \\ 1: can be write \\
  [3] READ_REE2_HP_MSPI_PADCTRL — Configures hp_mspi_padctrl registers read permission in ree2 mode.\\ 0: can not be read \\ 1: can be read \\
  [2] READ_REE1_HP_MSPI_PADCTRL — Configures hp_mspi_padctrl registers read permission in ree1 mode.\\ 0: can not be read \\ 1: can be read \\
  [1] READ_REE0_HP_MSPI_PADCTRL — Configures hp_mspi_padctrl registers read permission in ree0 mode.\\ 0: can not be read \\ 1: can be read \\
  [0] READ_TEE_HP_MSPI_PADCTRL — Configures hp_mspi_padctrl registers read permission in tee mode.\\ 0: can not be read \\ 1: can be read \\
0x84 HP_INTRMTX_CTRL reset 0x11 — hp_intrmtx read/write control register
  [8] HP_INTRMTX_LOCK — Set 1 to lock hp_intrmtx peri_apm configuration
  [7] WRITE_REE2_HP_INTRMTX — Configures hp_intrmtx registers write permission in ree2 mode.\\ 0: can not be write \\ 1: can be write \\
  [6] WRITE_REE1_HP_INTRMTX — Configures hp_intrmtx registers write permission in ree1 mode.\\ 0: can not be write \\ 1: can be write \\
  [5] WRITE_REE0_HP_INTRMTX — Configures hp_intrmtx registers write permission in ree0 mode.\\ 0: can not be write \\ 1: can be write \\
  [4] WRITE_TEE_HP_INTRMTX — Configures hp_intrmtx registers write permission in tee mode.\\ 0: can not be write \\ 1: can be write \\
  [3] READ_REE2_HP_INTRMTX — Configures hp_intrmtx registers read permission in ree2 mode.\\ 0: can not be read \\ 1: can be read \\
  [2] READ_REE1_HP_INTRMTX — Configures hp_intrmtx registers read permission in ree1 mode.\\ 0: can not be read \\ 1: can be read \\
  [1] READ_REE0_HP_INTRMTX — Configures hp_intrmtx registers read permission in ree0 mode.\\ 0: can not be read \\ 1: can be read \\
  [0] READ_TEE_HP_INTRMTX — Configures hp_intrmtx registers read permission in tee mode.\\ 0: can not be read \\ 1: can be read \\
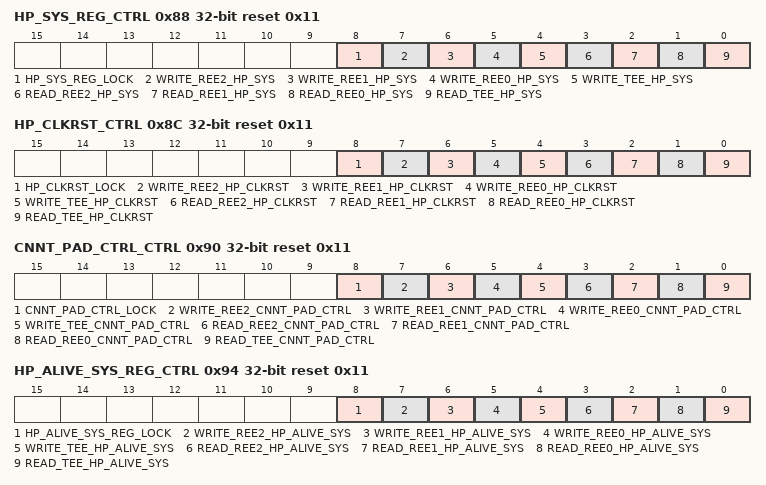
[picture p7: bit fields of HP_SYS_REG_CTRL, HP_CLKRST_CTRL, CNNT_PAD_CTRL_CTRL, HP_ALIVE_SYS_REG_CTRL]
0x88 HP_SYS_REG_CTRL reset 0x11 — hp_sys_reg read/write control register
  [8] HP_SYS_REG_LOCK — Set 1 to lock hp_sys_reg peri_apm configuration
  [7] WRITE_REE2_HP_SYS — Configures hp_sys_reg registers write permission in ree2 mode.\\ 0: can not be write \\ 1: can be write \\
  [6] WRITE_REE1_HP_SYS — Configures hp_sys_reg registers write permission in ree1 mode.\\ 0: can not be write \\ 1: can be write \\
  [5] WRITE_REE0_HP_SYS — Configures hp_sys_reg registers write permission in ree0 mode.\\ 0: can not be write \\ 1: can be write \\
  [4] WRITE_TEE_HP_SYS — Configures hp_sys_reg registers write permission in tee mode.\\ 0: can not be write \\ 1: can be write \\
  [3] READ_REE2_HP_SYS — Configures hp_sys_reg registers read permission in ree2 mode.\\ 0: can not be read \\ 1: can be read \\
  [2] READ_REE1_HP_SYS — Configures hp_sys_reg registers read permission in ree1 mode.\\ 0: can not be read \\ 1: can be read \\
  [1] READ_REE0_HP_SYS — Configures hp_sys_reg registers read permission in ree0 mode.\\ 0: can not be read \\ 1: can be read \\
  [0] READ_TEE_HP_SYS — Configures hp_sys_reg registers read permission in tee mode.\\ 0: can not be read \\ 1: can be read \\
0x8C HP_CLKRST_CTRL reset 0x11 — hp_clkrst read/write control register
  [8] HP_CLKRST_LOCK — Set 1 to lock hp_clkrst peri_apm configuration
  [7] WRITE_REE2_HP_CLKRST — Configures hp_clkrst registers write permission in ree2 mode.\\ 0: can not be write \\ 1: can be write \\
  [6] WRITE_REE1_HP_CLKRST — Configures hp_clkrst registers write permission in ree1 mode.\\ 0: can not be write \\ 1: can be write \\
  [5] WRITE_REE0_HP_CLKRST — Configures hp_clkrst registers write permission in ree0 mode.\\ 0: can not be write \\ 1: can be write \\
  [4] WRITE_TEE_HP_CLKRST — Configures hp_clkrst registers write permission in tee mode.\\ 0: can not be write \\ 1: can be write \\
  [3] READ_REE2_HP_CLKRST — Configures hp_clkrst registers read permission in ree2 mode.\\ 0: can not be read \\ 1: can be read \\
  [2] READ_REE1_HP_CLKRST — Configures hp_clkrst registers read permission in ree1 mode.\\ 0: can not be read \\ 1: can be read \\
  [1] READ_REE0_HP_CLKRST — Configures hp_clkrst registers read permission in ree0 mode.\\ 0: can not be read \\ 1: can be read \\
  [0] READ_TEE_HP_CLKRST — Configures hp_clkrst registers read permission in tee mode.\\ 0: can not be read \\ 1: can be read \\
0x90 CNNT_PAD_CTRL_CTRL reset 0x11 — cnnt_pad_ctrl read/write control register
  [8] CNNT_PAD_CTRL_LOCK — Set 1 to lock cnnt_pad_ctrl peri_apm configuration
  [7] WRITE_REE2_CNNT_PAD_CTRL — Configures cnnt_pad_ctrl registers write permission in ree2 mode.\\ 0: can not be write \\ 1: can be write \\
  [6] WRITE_REE1_CNNT_PAD_CTRL — Configures cnnt_pad_ctrl registers write permission in ree1 mode.\\ 0: can not be write \\ 1: can be write \\
  [5] WRITE_REE0_CNNT_PAD_CTRL — Configures cnnt_pad_ctrl registers write permission in ree0 mode.\\ 0: can not be write \\ 1: can be write \\
  [4] WRITE_TEE_CNNT_PAD_CTRL — Configures cnnt_pad_ctrl registers write permission in tee mode.\\ 0: can not be write \\ 1: can be write \\
  [3] READ_REE2_CNNT_PAD_CTRL — Configures cnnt_pad_ctrl registers read permission in ree2 mode.\\ 0: can not be read \\ 1: can be read \\
  [2] READ_REE1_CNNT_PAD_CTRL — Configures cnnt_pad_ctrl registers read permission in ree1 mode.\\ 0: can not be read \\ 1: can be read \\
  [1] READ_REE0_CNNT_PAD_CTRL — Configures cnnt_pad_ctrl registers read permission in ree0 mode.\\ 0: can not be read \\ 1: can be read \\
  [0] READ_TEE_CNNT_PAD_CTRL — Configures cnnt_pad_ctrl registers read permission in tee mode.\\ 0: can not be read \\ 1: can be read \\
0x94 HP_ALIVE_SYS_REG_CTRL reset 0x11 — hp_alive_sys_reg read/write control register
  [8] HP_ALIVE_SYS_REG_LOCK — Set 1 to lock hp_alive_sys_reg peri_apm configuration
  [7] WRITE_REE2_HP_ALIVE_SYS — Configures hp_alive_sys_reg registers write permission in ree2 mode.\\ 0: can not be write \\ 1: can be write \\
  [6] WRITE_REE1_HP_ALIVE_SYS — Configures hp_alive_sys_reg registers write permission in ree1 mode.\\ 0: can not be write \\ 1: can be write \\
  [5] WRITE_REE0_HP_ALIVE_SYS — Configures hp_alive_sys_reg registers write permission in ree0 mode.\\ 0: can not be write \\ 1: can be write \\
  [4] WRITE_TEE_HP_ALIVE_SYS — Configures hp_alive_sys_reg registers write permission in tee mode.\\ 0: can not be write \\ 1: can be write \\
  [3] READ_REE2_HP_ALIVE_SYS — Configures hp_alive_sys_reg registers read permission in ree2 mode.\\ 0: can not be read \\ 1: can be read \\
  [2] READ_REE1_HP_ALIVE_SYS — Configures hp_alive_sys_reg registers read permission in ree1 mode.\\ 0: can not be read \\ 1: can be read \\
  [1] READ_REE0_HP_ALIVE_SYS — Configures hp_alive_sys_reg registers read permission in ree0 mode.\\ 0: can not be read \\ 1: can be read \\
  [0] READ_TEE_HP_ALIVE_SYS — Configures hp_alive_sys_reg registers read permission in tee mode.\\ 0: can not be read \\ 1: can be read \\
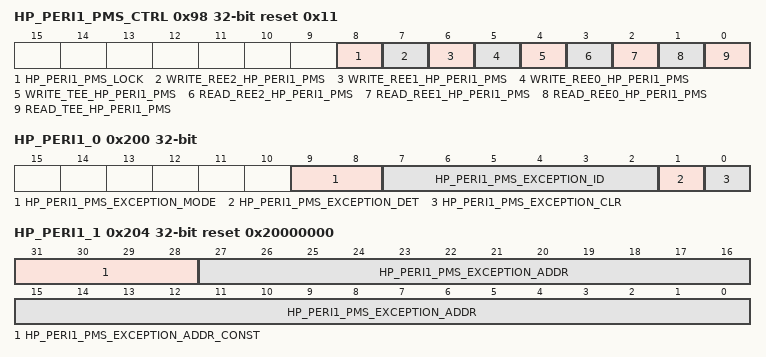
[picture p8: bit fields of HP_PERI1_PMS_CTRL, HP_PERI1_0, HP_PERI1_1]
0x98 HP_PERI1_PMS_CTRL access per field reset 0x11 — hp_peri1_pms read/write control register
  [8] HP_PERI1_PMS_LOCK rw — Set 1 to lock hp_peri1_pms peri_apm configuration
  [7] WRITE_REE2_HP_PERI1_PMS ro — Configures hp_peri1_pms registers write permission in ree2 mode.\\ 0: can not be write \\ 1: can be write \\
  [6] WRITE_REE1_HP_PERI1_PMS ro — Configures hp_peri1_pms registers write permission in ree1 mode.\\ 0: can not be write \\ 1: can be write \\
  [5] WRITE_REE0_HP_PERI1_PMS ro — Configures hp_peri1_pms registers write permission in ree0 mode.\\ 0: can not be write \\ 1: can be write \\
  [4] WRITE_TEE_HP_PERI1_PMS rw — Configures hp_peri1_pms registers write permission in tee mode.\\ 0: can not be write \\ 1: can be write \\
  [3] READ_REE2_HP_PERI1_PMS ro — Configures hp_peri1_pms registers read permission in ree2 mode.\\ 0: can not be read \\ 1: can be read \\
  [2] READ_REE1_HP_PERI1_PMS ro — Configures hp_peri1_pms registers read permission in ree1 mode.\\ 0: can not be read \\ 1: can be read \\
  [1] READ_REE0_HP_PERI1_PMS ro — Configures hp_peri1_pms registers read permission in ree0 mode.\\ 0: can not be read \\ 1: can be read \\
  [0] READ_TEE_HP_PERI1_PMS rw — Configures hp_peri1_pms registers read permission in tee mode.\\ 0: can not be read \\ 1: can be read \\
0x200 HP_PERI1_0 access per field — HP_PERI1 PMS configuration & info register
  [9:8] HP_PERI1_PMS_EXCEPTION_MODE ro — Represents the security mode when hp_peri1 pms has been triggered.\\
  [7:2] HP_PERI1_PMS_EXCEPTION_ID ro — Represents the master id when hp_peri1 pms has been triggered.\\
  [1] HP_PERI1_PMS_EXCEPTION_DET ro — Represents whether the hp_peri1 pms has been triggered.\\ 0: No triggered\\ 1: Has been triggered\\
  [0] HP_PERI1_PMS_EXCEPTION_CLR wo — Configures whether or not to clear hp_peri1 peri_pms_record_reg.\\ 0: No clear\\ 1: Clear peri_pms_record_reg\\
0x204 HP_PERI1_1 ro reset 0x20000000 — HP_PERI1 PMS exception addr record register
  [31:28] HP_PERI1_PMS_EXCEPTION_ADDR_CONST — Represents the access address (bit31~bit28) when hp_peri1 pms has been triggered.\\
  [27:0] HP_PERI1_PMS_EXCEPTION_ADDR — Represents the access address (bit27~bit0) when hp_peri1 pms has been triggered.\\
0x300 INT_EN — APM interrupt enable register
  [0] HP_PERI1_PMS_INT_EN — Configures to enable hp_peri1 pms interrupt.\\ 0: disable \\ 1: enable \\
0xFF0 BUS_ERR_CONF — Clock gating register
  [0] BUS_ERR_RESP_EN — Configures whether return error response to cpu when access blocked 0: disable error response \\ 1: enable error response \\
0xFF8 CLOCK_GATE reset 0x1 — Clock gating register
  [0] CLK_EN — Configures whether to keep the clock always on.\\ 0: enable automatic clock gating \\ 1: keep the clock always on \\
0xFFC DATE reset 0x2509220 — Version control register
  [27:0] DATE
